# STM32WL3Rx register map
File version: 1.0
Registers are 32-bit, read-write, reset 0x0 unless marked. A register's access mark holds for its fields unless they carry their own. Offsets are from the block's base; [hi:lo] are bit positions; {n}, {i} and the like mark numbered series.

## MR_SUBG_RADIO
Base 0x49000000
0x00 RF_FSM0_TIMEOUT — (@ 0x00000000) RF_FSM0_TIMEOUT register
  [7:0] ENA_RFREG_TIMER
0x04 RF_FSM1_TIMEOUT — (@ 0x00000004) RF_FSM1_TIMEOUT register
  [7:0] SYNTH_SETUP_TIMER
0x08 RF_FSM2_TIMEOUT — (@ 0x00000008) RF_FSM2_TIMEOUT register
  [7:0] VCO_CALIB_LOCK_TIMER
0x0C RF_FSM3_TIMEOUT — (@ 0x0000000C) RF_FSM3_TIMEOUT register
  [7:0] VCO_LOCK_TIMER
0x10 RF_FSM4_TIMEOUT — (@ 0x00000010) RF_FSM4_TIMEOUT register
  [7:0] EN_RX_TIMER
0x14 RF_FSM5_TIMEOUT — (@ 0x00000014) RF_FSM5_TIMEOUT register
  [7:0] EN_PA_TIMER
0x18 RF_FSM6_TIMEOUT — (@ 0x00000018) RF_FSM6_TIMEOUT register
  [7:0] PA_DWN_ANA_TIMER
0x1C RF_FSM7_TIMEOUT — (@ 0x0000001C) RF_FSM7_TIMEOUT register
  [7:0] EN_LNA_TIMER
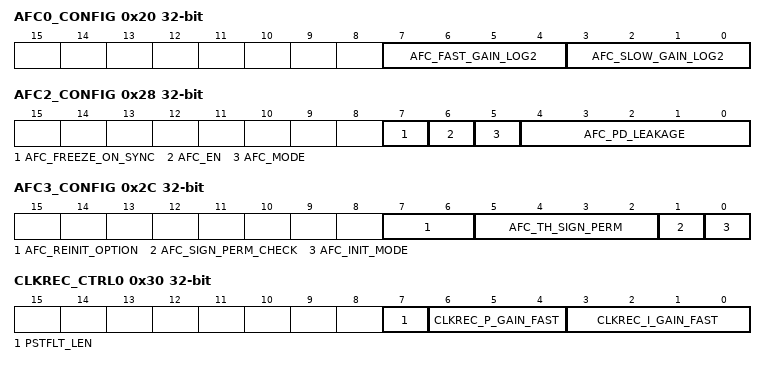
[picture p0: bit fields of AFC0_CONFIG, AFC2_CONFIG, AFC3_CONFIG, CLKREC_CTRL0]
0x20 AFC0_CONFIG — (@ 0x00000020) AFC0_CONFIG register
  [7:4] AFC_FAST_GAIN_LOG2, [3:0] AFC_SLOW_GAIN_LOG2
0x24 AFC1_CONFIG — (@ 0x00000024) AFC1_CONFIG register
  [7:0] AFC_FAST_PERIOD
0x28 AFC2_CONFIG — (@ 0x00000028) AFC2_CONFIG register
  [7] AFC_FREEZE_ON_SYNC, [6] AFC_EN, [5] AFC_MODE, [4:0] AFC_PD_LEAKAGE
0x2C AFC3_CONFIG — (@ 0x0000002C) AFC3_CONFIG register
  [7:6] AFC_REINIT_OPTION, [5:2] AFC_TH_SIGN_PERM, [1] AFC_SIGN_PERM_CHECK, [0] AFC_INIT_MODE
0x30 CLKREC_CTRL0 — (@ 0x00000030) CLKREC_CTRL0 register
  [7] PSTFLT_LEN, [6:4] CLKREC_P_GAIN_FAST, [3:0] CLKREC_I_GAIN_FAST
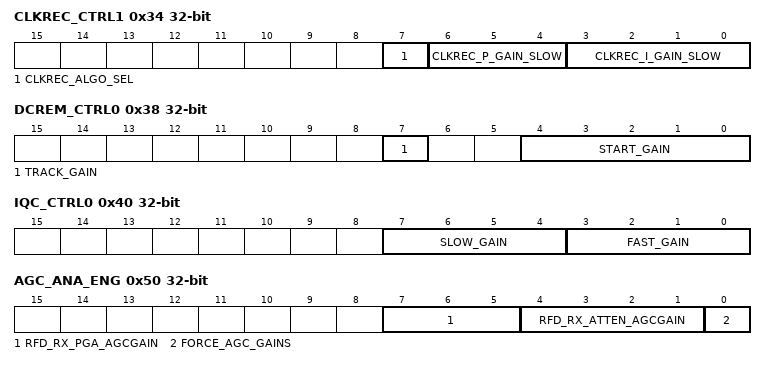
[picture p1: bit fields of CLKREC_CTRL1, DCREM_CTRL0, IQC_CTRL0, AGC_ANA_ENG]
0x34 CLKREC_CTRL1 — (@ 0x00000034) CLKREC_CTRL1 register
  [7] CLKREC_ALGO_SEL, [6:4] CLKREC_P_GAIN_SLOW, [3:0] CLKREC_I_GAIN_SLOW
0x38 DCREM_CTRL0 — (@ 0x00000038) DCREM_CTRL0 register
  [7] TRACK_GAIN, [4:0] START_GAIN
0x3C DCREM_CTRL1 — (@ 0x0000003C) DCREM_CTRL1 register
  [3:0] LN2TIME2SET
0x40 IQC_CTRL0 — (@ 0x00000040) IQC_CTRL0 register
  [7:4] SLOW_GAIN, [3:0] FAST_GAIN
0x44 IQC_CTRL1 — (@ 0x00000044) IQC_CTRL1 register
  [7:0] QPD_ATTACK
0x48 IQC_CTRL2 — (@ 0x00000048) IQC_CTRL2 register
  [7:0] QPD_DECAY
0x4C IQC_CTRL3 — (@ 0x0000004C) IQC_CTRL3 register
  [3:0] FAST_TIME
0x50 AGC_ANA_ENG — (@ 0x00000050) AGC_ANA_ENG register
  [7:5] RFD_RX_PGA_AGCGAIN, [4:1] RFD_RX_ATTEN_AGCGAIN, [0] FORCE_AGC_GAINS
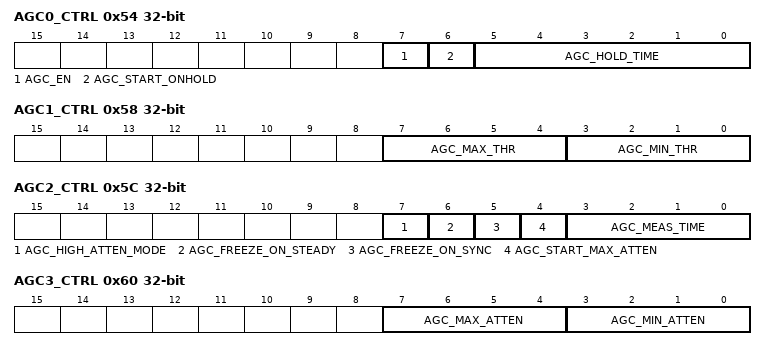
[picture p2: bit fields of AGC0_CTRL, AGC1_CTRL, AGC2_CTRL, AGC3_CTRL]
0x54 AGC0_CTRL — (@ 0x00000054) AGC0_CTRL register
  [7] AGC_EN, [6] AGC_START_ONHOLD, [5:0] AGC_HOLD_TIME
0x58 AGC1_CTRL — (@ 0x00000058) AGC1_CTRL register
  [7:4] AGC_MAX_THR, [3:0] AGC_MIN_THR
0x5C AGC2_CTRL — (@ 0x0000005C) AGC2_CTRL register
  [7] AGC_HIGH_ATTEN_MODE, [6] AGC_FREEZE_ON_STEADY, [5] AGC_FREEZE_ON_SYNC, [4] AGC_START_MAX_ATTEN, [3:0] AGC_MEAS_TIME
0x60 AGC3_CTRL — (@ 0x00000060) AGC3_CTRL register
  [7:4] AGC_MAX_ATTEN, [3:0] AGC_MIN_ATTEN
0x64 AGC4_CTRL — (@ 0x00000064) AGC4_CTRL register
  [3:0] AGC_FREEZE_THR
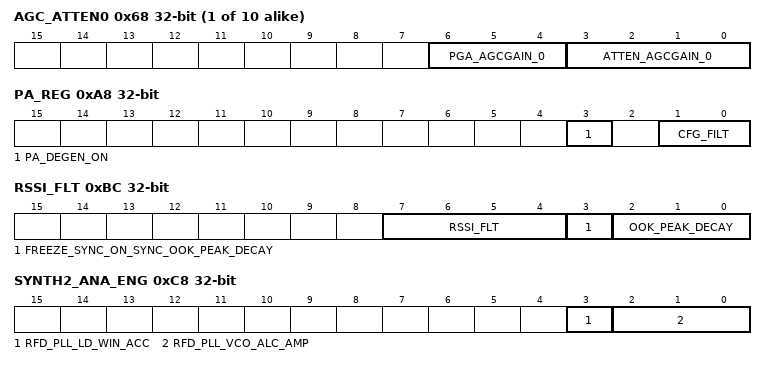
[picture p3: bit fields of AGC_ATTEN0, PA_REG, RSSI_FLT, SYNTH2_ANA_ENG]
{0x68+4i} AGC_ATTEN{i} (i=0..9) — (@ {0x68+4i}) AGC_ATTEN{i} register
  [6:4] PGA_AGCGAIN_{i}, [3:0] ATTEN_AGCGAIN_{i}
{0x8C+4i} AGC{i}_ATTEN_TRIM (i=1..4) — (@ {0x8C+4i}) AGC{i}_ATTEN_TRIM register
  [7:0] AGC{i}_ATTEN_TRIM_IN
0xA0 AGC_PGA_HWTRIM_OUT — (@ 0x000000A0) AGC_PGA_HWTRIM_OUT register
  [3:0] AGC_HW_PGA_TRIM
0xA8 PA_REG — (@ 0x000000A8) PA_REG register
  [3] PA_DEGEN_ON, [1:0] CFG_FILT
0xAC PA_HWTRIM_OUT — (@ 0x000000AC) PA_HWTRIM_OUT register
  [7:4] PA_HW_DEGEN_TRIM
0xBC RSSI_FLT — (@ 0x000000BC) RSSI_FLT register
  [7:4] RSSI_FLT, [3] FREEZE_SYNC_ON_SYNC_OOK_PEAK_DECAY, [2:0] OOK_PEAK_DECAY
0xC8 SYNTH2_ANA_ENG — (@ 0x000000C8) SYNTH2_ANA_ENG register
  [3] RFD_PLL_LD_WIN_ACC, [2:0] RFD_PLL_VCO_ALC_AMP
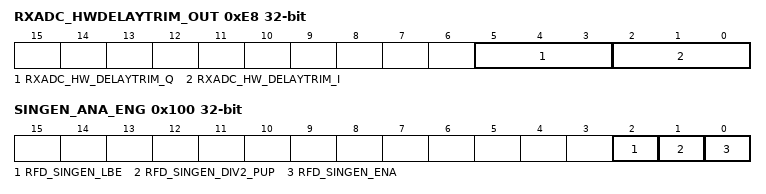
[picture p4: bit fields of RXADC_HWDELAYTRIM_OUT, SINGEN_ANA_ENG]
0xE8 RXADC_HWDELAYTRIM_OUT — (@ 0x000000E8) RXADC_HWDELAYTRIM_OUT register
  [5:3] RXADC_HW_DELAYTRIM_Q, [2:0] RXADC_HW_DELAYTRIM_I
0xF4 RX_AAF_HWTRIM_OUT — (@ 0x000000F4) RX_AAF_HWTRIM_OUT register
  [3:0] AAF_HW_FCTRIM
0x100 SINGEN_ANA_ENG — (@ 0x00000100) SINGEN_ANA_ENG register
  [2] RFD_SINGEN_LBE, [1] RFD_SINGEN_DIV2_PUP, [0] RFD_SINGEN_ENA
0x108 RF_INFO_OUT — (@ 0x00000108) RF_INFO_OUT register
  [7:4] RFSUBG_ID
0x10C RFANA_PLL_IN — (@ 0x0000010C) RFANA_PLL_IN register
  [6] DIV12_SEL
0x124 RF_FSM8_TIMEOUT — (@ 0x00000124) RF_FSM8_TIMEOUT register
  [7:0] SYNTH_PDWN_TIMER
0x128 RF_FSM9_TIMEOUT — (@ 0x00000128) RF_FSM9_TIMEOUT register
  [7:0] END_RX_TIMER
0x12C RF_FSM10_TIMEOUT — (@ 0x0000012C) RF_FSM10_TIMEOUT register
  [7:0] END_TX_TIMER
0x144 SUBG_DIG_CTRL0 — (@ 0x00000144) SUBG_DIG_CTRL0 register
  [0] FORCE_GPIO_OUTPUT
